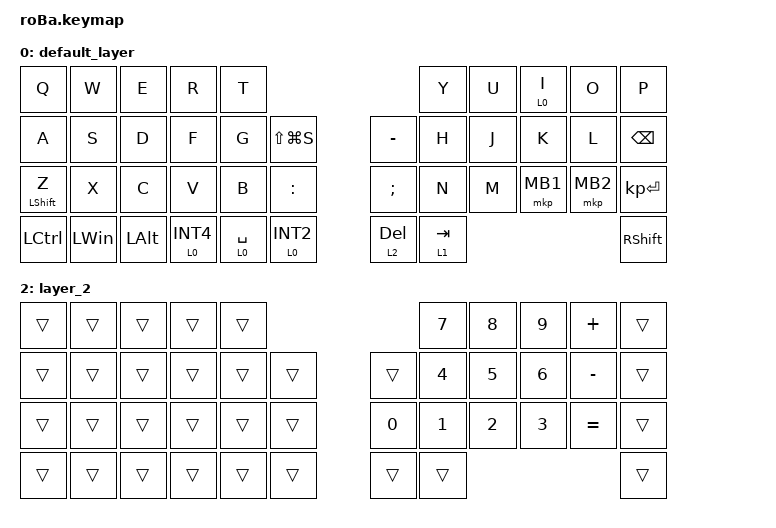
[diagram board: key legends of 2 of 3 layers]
#include <behaviors.dtsi>
#include <dt-bindings/zmk/keys.h>
#include <dt-bindings/zmk/pointing.h>
#include <dt-bindings/zmk/pointing.h>

#define MOUSE 4
#define SCROLL 5
#define NUM 6

&mt {
    flavor = "balanced";
    quick-tap-ms = <0>;
};

&msc {
    x-input-code = <INPUT_REL_HWHEEL>;
    trigger-period-ms = <0>;
    acceleration-exponent = <1>;
    delay-ms = <100>;
    time-to-max-speed-ms = <250>;
};

/ {
    combos {
        compatible = "zmk,combos";

        tab {
            bindings = <&kp TAB>;
            key-positions = <11 12>;
        };

        shift_tab {
            bindings = <&kp LS(TAB)>;
            key-positions = <12 13>;
        };

        muhennkann {
            bindings = <&to_layer_0 INT_MUHENKAN>;
            key-positions = <11 10>;
        };

        double_quotation {
            bindings = <&kp DOUBLE_QUOTES>;
            key-positions = <20 21>;
        };

        eq {
            bindings = <&kp EQUAL>;
            key-positions = <24 25>;
        };
    };

    macros {
        to_layer_0: to_layer_0 {
            compatible = "zmk,behavior-macro-one-param";
            #binding-cells = <1>;
            bindings = <&to 0 &macro_param_1to1 &kp MACRO_PLACEHOLDER>;
            label = "TO_LAYER_0";
        };
    };

    behaviors {
        lt_to_layer_0: lt_to_layer_0 {
            compatible = "zmk,behavior-hold-tap";
            label = "LAYER_TAP_TO_0";
            bindings = <&mo>, <&to_layer_0>;

            #binding-cells = <2>;
            tapping-term-ms = <200>;
        };

        mscscrool: mscscrool {
            compatible = "zmk,behavior-hold-tap";
            label = "MSCSCROOL";
            bindings = <&msc>, <&mkp>;

            #binding-cells = <2>;
            tapping-term-ms = <200>;
            quick-tap-ms = <1>;
            require-prior-idle-ms = <1>;
        };
    };

    keymap {
        compatible = "zmk,keymap";

        default_layer {
            bindings = <
&kp Q             &kp W         &kp E         &kp R                  &kp T                                                  &kp Y      &kp U  &lt 0 I   &kp O     &kp P
&kp A             &kp S         &kp D         &kp F                  &kp G        &kp LS(LG(S))              &kp MINUS      &kp H      &kp J  &kp K     &kp L     &kp BACKSPACE
&mt LEFT_SHIFT Z  &kp X         &kp C         &kp V                  &kp B        &kp COLON                  &kp SEMICOLON  &kp N      &kp M  &mkp MB1  &mkp MB2  &kp KP_ENTER
&kp LCTRL         &kp LEFT_WIN  &kp LEFT_ALT  &lt_to_layer_0 0 INT4  &lt 0 SPACE  &lt_to_layer_0 0 INT2      &lt 2 DEL      &lt 1 TAB                             &kp RIGHT_SHIFT
            >;

            sensor-bindings = <&inc_dec_kp PG_UP PAGE_DOWN>;
        };

        scroll_layer {
            bindings = <
&none  &none  &none  &none  &none                    &none  &none                    &none  &none  &none
&none  &none  &none  &none  &none  &none      &none  &none  &none                    &none  &none  &none
&none  &none  &none  &none  &none  &none      &none  &none  &pointing_device_scroll  &none  &none  &none
&none
            >;
        };

        layer_2 {
            bindings = <
&trans  &trans  &trans  &trans  &trans                      &kp N7        &kp N8  &kp N9  &kp PLUS   &trans
&trans  &trans  &trans  &trans  &trans  &trans      &trans  &kp N4        &kp N5  &kp N6  &kp MINUS  &trans
&trans  &trans  &trans  &trans  &trans  &trans      &kp N0  &kp NUMBER_1  &kp N2  &kp N3  &kp EQUAL  &trans
&trans  &trans  &trans  &trans  &trans  &trans      &trans  &trans                                   &trans
            >;
        };
    };

    behaviors {
        pointing_device_scroll {
            compatible = "zmk,behavior-momentary";
            label = "Enable Scroll Mode";
            bindings = <&pointing_device_scroll_up &pointing_device_scroll_down>;
        };
    };
};
